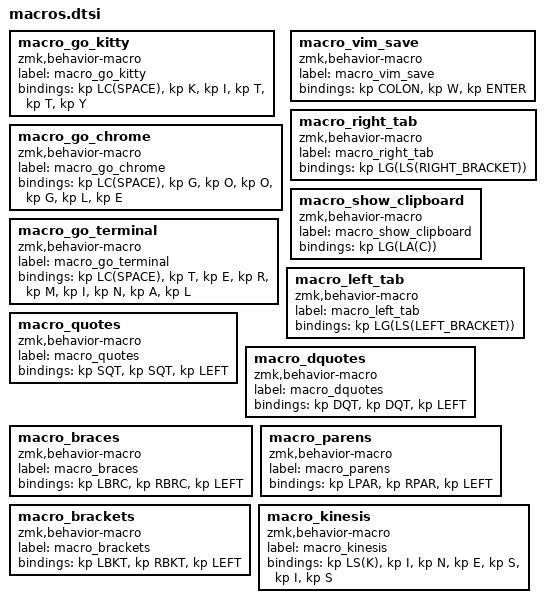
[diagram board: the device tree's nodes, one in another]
macro_go_kitty: macro_go_kitty{
compatible = "zmk,behavior-macro";
label = "macro_go_kitty";
#binding-cells = <0>;
bindings = <&kp LC(SPACE)>, <&kp K>, <&kp I>, <&kp T>, <&kp T>, <&kp Y>;
};
macro_go_chrome: macro_go_chrome{
compatible = "zmk,behavior-macro";
label = "macro_go_chrome";
#binding-cells = <0>;
bindings = <&kp LC(SPACE)>, <&kp G>, <&kp O>, <&kp O>, <&kp G>, <&kp L>, <&kp E>;
};
macro_go_terminal: macro_go_terminal{
compatible = "zmk,behavior-macro";
label = "macro_go_terminal";
#binding-cells = <0>;
bindings = <&kp LC(SPACE)>, <&kp T>, <&kp E>, <&kp R>, <&kp M>, <&kp I>, <&kp N>, <&kp A>, <&kp L>;
};
macro_vim_save: macro_vim_save{
compatible = "zmk,behavior-macro";
label = "macro_vim_save";
#binding-cells = <0>;
bindings = <&kp COLON>, <&kp W>, <&kp ENTER>;
};
macro_right_tab: macro_right_tab{
compatible = "zmk,behavior-macro";
label = "macro_right_tab";
#binding-cells = <0>;
bindings = <&kp LG(LS(RIGHT_BRACKET))>;
};
macro_show_clipboard: macro_show_clipboard{
compatible = "zmk,behavior-macro";
label = "macro_show_clipboard";
#binding-cells = <0>;
bindings = <&kp LG(LA(C))>;
};
macro_left_tab: macro_left_tab{
compatible = "zmk,behavior-macro";
label = "macro_left_tab";
#binding-cells = <0>;
bindings = <&kp LG(LS(LEFT_BRACKET))>;
};
macro_quotes: macro_quotes{
compatible = "zmk,behavior-macro";
label = "macro_quotes";
#binding-cells = <0>;
bindings = <&kp SQT>, <&kp SQT>, <&kp LEFT>;
};
macro_dquotes: macro_dquotes{
compatible = "zmk,behavior-macro";
label = "macro_dquotes";
#binding-cells = <0>;
bindings = <&kp DQT>, <&kp DQT>, <&kp LEFT>;
};
macro_braces: macro_braces{
compatible = "zmk,behavior-macro";
label = "macro_braces";
#binding-cells = <0>;
bindings = <&kp LBRC>, <&kp RBRC>, <&kp LEFT>;
};
macro_parens: macro_parens{
compatible = "zmk,behavior-macro";
label = "macro_parens";
#binding-cells = <0>;
bindings = <&kp LPAR>, <&kp RPAR>, <&kp LEFT>;
};
macro_brackets: macro_brackets{
compatible = "zmk,behavior-macro";
label = "macro_brackets";
#binding-cells = <0>;
bindings = <&kp LBKT>, <&kp RBKT>, <&kp LEFT>;
};
macro_kinesis: macro_kinesis{
compatible = "zmk,behavior-macro";
label = "macro_kinesis";
#binding-cells = <0>;
bindings = <&kp LS(K)>, <&kp I>, <&kp N>, <&kp E>, <&kp S>, <&kp I>, <&kp S>;
};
